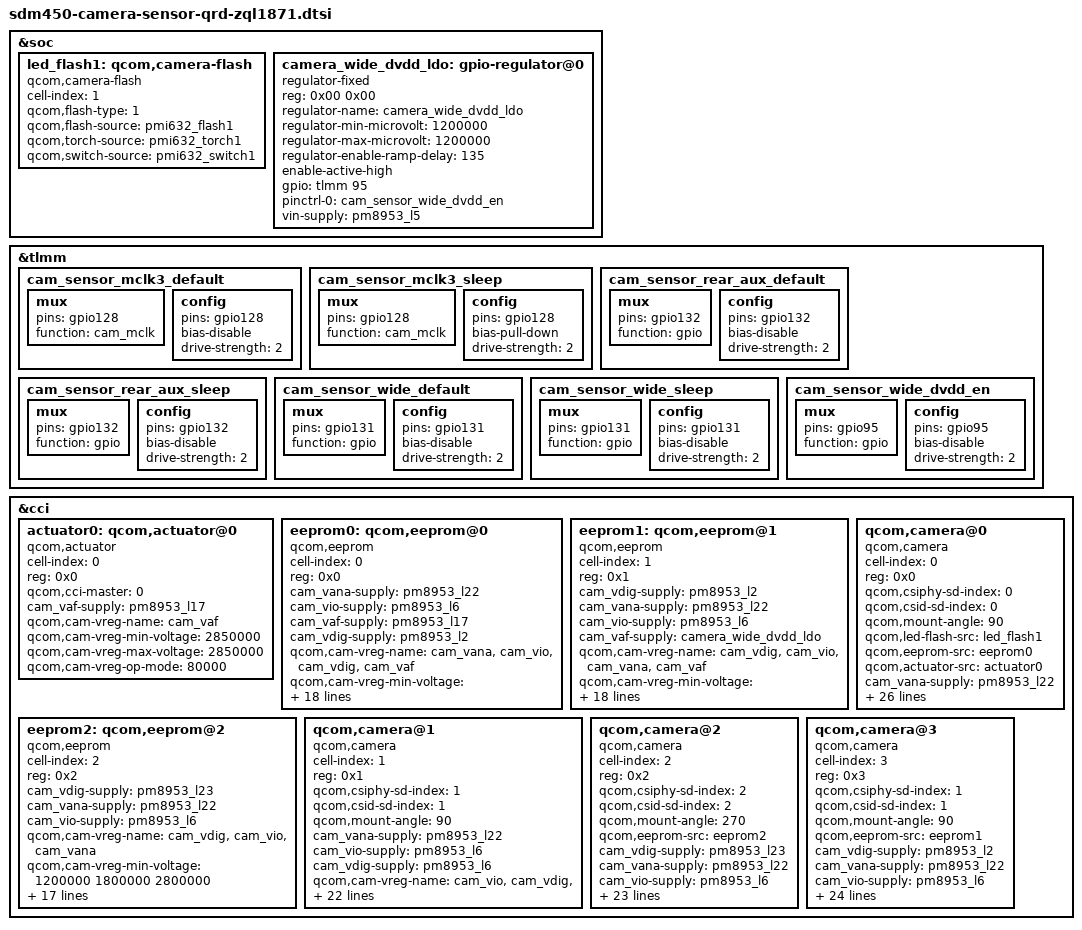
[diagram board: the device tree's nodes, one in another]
/*
 * Copyright (c) 2015-2016, 2018-2019 The Linux Foundation. All rights reserved.
 *
 * This program is free software; you can redistribute it and/or modify
 * it under the terms of the GNU General Public License version 2 and
 * only version 2 as published by the Free Software Foundation.
 *
 * This program is distributed in the hope that it will be useful,
 * but WITHOUT ANY WARRANTY; without even the implied warranty of
 * MERCHANTABILITY or FITNESS FOR A PARTICULAR PURPOSE.  See the
 * GNU General Public License for more details.
 */
/*HS70 code for HS70-58 modify flash switch by chengzhi at 2019/10/22 start*/
&soc {
	led_flash1: qcom,camera-flash {
		cell-index = <1>;
		compatible = "qcom,camera-flash";
		qcom,flash-type = <1>;
		qcom,flash-source = <&pmi632_flash1>;
		qcom,torch-source = <&pmi632_torch1>;
		qcom,switch-source = <&pmi632_switch1>;
	};

	camera_wide_dvdd_ldo: gpio-regulator@0 {
		compatible = "regulator-fixed";
		reg = <0x00 0x00>;
		regulator-name = "camera_wide_dvdd_ldo";
		regulator-min-microvolt = <1200000>;
		regulator-max-microvolt = <1200000>;
		regulator-enable-ramp-delay = <135>;
		enable-active-high;
		gpio = <&tlmm 95 0>;
		pinctrl-names = "default";
		pinctrl-0 = <&cam_sensor_wide_dvdd_en>;
		vin-supply = <&pm8953_l5>;
	};
};
/*HS70 code for HS70-58 modify flash switch by chengzhi at 2019/10/22 end*/

&tlmm{
	cam_sensor_mclk3_default: cam_sensor_mclk3_default {
		/* MCLK3 */
		mux {
			pins = "gpio128";
			function = "cam_mclk";
		};

		config {
			pins = "gpio128";
			bias-disable; /* No PULL */
			drive-strength = <2>; /* 2 MA */
		};
	};

	cam_sensor_mclk3_sleep: cam_sensor_mclk3_sleep {
		/* MCLK3 */
		mux {
			pins = "gpio128";
			function = "cam_mclk";
		};

		config {
			pins = "gpio128";
			bias-pull-down; /* PULL DOWN */
			drive-strength = <2>; /* 2 MA */
		};
	};

	cam_sensor_rear_aux_default: cam_sensor_rear_aux_default {
		/* RESET, STANDBY */
		mux {
			pins = "gpio132";
			function = "gpio";
		};

		config {
			pins = "gpio132";
			bias-disable; /* No PULL */
			drive-strength = <2>; /* 2 MA */
		};
	};

	cam_sensor_rear_aux_sleep: cam_sensor_rear_aux_sleep {
		/* RESET, STANDBY */
		mux {
			pins = "gpio132";
			function = "gpio";
		};

		config {
			pins = "gpio132";
			bias-disable; /* No PULL */
			drive-strength = <2>; /* 2 MA */
		};
	};

	cam_sensor_wide_default: cam_sensor_wide_default {
		/* RESET, STANDBY */
		mux {
			pins = "gpio131";
			function = "gpio";
		};

		config {
			pins = "gpio131";
			bias-disable; /* No PULL */
			drive-strength = <2>; /* 2 MA */
		};
	};

	cam_sensor_wide_sleep: cam_sensor_wide_sleep {
		/* RESET, STANDBY */
		mux {
			pins = "gpio131";
			function = "gpio";
		};

		config {
			pins = "gpio131";
			bias-disable; /* No PULL */
			drive-strength = <2>; /* 2 MA */
		};
	};

	cam_sensor_wide_dvdd_en: cam_sensor_wide_dvdd_en {
		/* RESET, STANDBY */
		mux {
			pins = "gpio95";
			function = "gpio";
		};

		config {
			pins = "gpio95";
			bias-disable; /* No PULL */
			drive-strength = <2>; /* 2 MA */
		};
	};
};

&cci {
	#address-cells = <1>;
	#size-cells = <0>;

	actuator0: qcom,actuator@0 {
		cell-index = <0>;
		reg = <0x0>;
		compatible = "qcom,actuator";
		qcom,cci-master = <0>;
		cam_vaf-supply = <&pm8953_l17>;
		qcom,cam-vreg-name = "cam_vaf";
		qcom,cam-vreg-min-voltage = <2850000>;
		qcom,cam-vreg-max-voltage = <2850000>;
		qcom,cam-vreg-op-mode = <80000>;
	};
	/*HS70 code for HS70-58 add otp node by chengzhi at 2019/10/22 start*/
	eeprom0: qcom,eeprom@0 {
		cell-index = <0>;
		compatible = "qcom,eeprom";
		reg = <0x0>;
		cam_vana-supply = <&pm8953_l22>;
		cam_vio-supply = <&pm8953_l6>;
		cam_vaf-supply = <&pm8953_l17>;
		cam_vdig-supply = <&pm8953_l2>;
		qcom,cam-vreg-name = "cam_vana", "cam_vio",
				"cam_vdig", "cam_vaf";
		qcom,cam-vreg-min-voltage = <2800000 1800000 1050000 2850000>;
		qcom,cam-vreg-max-voltage = <2800000 1800000 1200000 2850000>;
		qcom,cam-vreg-op-mode = <80000 0 105000 100000>;
		pinctrl-names = "cam_default", "cam_suspend";
		pinctrl-0 = <&cam_sensor_mclk0_default
				&cam_sensor_rear_default>;
		pinctrl-1 = <&cam_sensor_mclk0_sleep
				&cam_sensor_rear_sleep>;
		gpios = <&tlmm 26 0>,
			<&tlmm 40 0>;
		qcom,gpio-reset = <1>;
		qcom,gpio-req-tbl-num = <0 1>;
		qcom,gpio-req-tbl-flags = <1 0>;
		qcom,gpio-req-tbl-label = "CAMIF_MCLK0",
			"CAM_RESET0";
		qcom,cci-master = <0>;
		status = "ok";
		clocks = <&clock_gcc clk_mclk0_clk_src>,
				<&clock_gcc clk_gcc_camss_mclk0_clk>;
		clock-names = "cam_src_clk", "cam_clk";
		qcom,clock-rates = <24000000 0>;
	};

	eeprom1: qcom,eeprom@1 {
		cell-index = <1>;
		compatible = "qcom,eeprom";
		reg = <0x1>;
		cam_vdig-supply = <&pm8953_l2>;
		cam_vana-supply = <&pm8953_l22>;
		cam_vio-supply = <&pm8953_l6>;
		cam_vaf-supply = <&camera_wide_dvdd_ldo>;
		qcom,cam-vreg-name = "cam_vdig", "cam_vio", "cam_vana", "cam_vaf";
		qcom,cam-vreg-min-voltage = <1050000 1800000 2800000 1200000>;
		qcom,cam-vreg-max-voltage = <1200000 1800000 2800000 1200000>;
		qcom,cam-vreg-op-mode = <105000 0 80000 105000>;
		pinctrl-names = "cam_default", "cam_suspend";
		pinctrl-0 = <&cam_sensor_mclk2_default
				&cam_sensor_wide_default>;
		pinctrl-1 = <&cam_sensor_mclk2_sleep
				&cam_sensor_wide_sleep>;
		gpios = <&tlmm 28 0>,
			<&tlmm 131 0>;
		qcom,gpio-reset = <1>;
		qcom,gpio-req-tbl-num = <0 1>;
		qcom,gpio-req-tbl-flags = <1 0>;
		qcom,gpio-req-tbl-label = "CAMIF_MCLK2",
					  "CAM_RESET3";
		qcom,cci-master = <1>;
		status = "ok";
		clocks = <&clock_gcc clk_mclk2_clk_src>,
			<&clock_gcc clk_gcc_camss_mclk2_clk>;
		clock-names = "cam_src_clk", "cam_clk";
		qcom,clock-rates = <24000000 0>;
	};

	eeprom2: qcom,eeprom@2 {
		cell-index = <2>;
		compatible = "qcom,eeprom";
		reg = <0x2>;
		cam_vdig-supply = <&pm8953_l23>;
		cam_vana-supply = <&pm8953_l22>;
		cam_vio-supply = <&pm8953_l6>;
		qcom,cam-vreg-name = "cam_vdig", "cam_vio", "cam_vana";
		qcom,cam-vreg-min-voltage = <1200000 1800000 2800000>;
		qcom,cam-vreg-max-voltage = <1200000 1800000 2800000>;
		qcom,cam-vreg-op-mode = <105000 0 80000>;
		pinctrl-names = "cam_default", "cam_suspend";
		pinctrl-0 = <&cam_sensor_mclk1_default
				&cam_sensor_front1_default>;
		pinctrl-1 = <&cam_sensor_mclk1_sleep
				&cam_sensor_front1_sleep>;
		gpios = <&tlmm 27 0>,
			<&tlmm 129 0>;
		qcom,gpio-reset = <1>;
		qcom,gpio-req-tbl-num = <0 1>;
		qcom,gpio-req-tbl-flags = <1 0>;
		qcom,gpio-req-tbl-label = "CAMIF_MCLK1",
					  "CAM_RESET2";
		qcom,cci-master = <1>;
		status = "ok";
		clocks = <&clock_gcc clk_mclk1_clk_src>,
			<&clock_gcc clk_gcc_camss_mclk1_clk>;
		clock-names = "cam_src_clk", "cam_clk";
		qcom,clock-rates = <24000000 0>;
	};
	/*HS70 code for HS70-58 add otp node by chengzhi at 2019/10/22 end*/
	qcom,camera@0 {
		cell-index = <0>;
		compatible = "qcom,camera";
		reg = <0x0>;
		qcom,csiphy-sd-index = <0>;
		qcom,csid-sd-index = <0>;
		qcom,mount-angle = <90>;
		qcom,led-flash-src = <&led_flash1>;
		qcom,eeprom-src = <&eeprom0>;
		qcom,actuator-src = <&actuator0>;
		cam_vana-supply = <&pm8953_l22>;
		cam_vio-supply = <&pm8953_l6>;
		cam_vaf-supply = <&pm8953_l17>;
		cam_vdig-supply = <&pm8953_l2>;
		qcom,cam-vreg-name = "cam_vana", "cam_vio",
				"cam_vdig", "cam_vaf";
		qcom,cam-vreg-min-voltage = <2800000 1800000 1050000 2850000>;
		qcom,cam-vreg-max-voltage = <2800000 1800000 1200000 2850000>;
		qcom,cam-vreg-op-mode = <80000 0 105000 100000>;
		pinctrl-names = "cam_default", "cam_suspend";
		pinctrl-0 = <&cam_sensor_mclk0_default
				&cam_sensor_rear_default>;
		pinctrl-1 = <&cam_sensor_mclk0_sleep
				&cam_sensor_rear_sleep>;
		gpios = <&tlmm 26 0>,
			<&tlmm 40 0>;
		qcom,gpio-reset = <1>;
		qcom,gpio-req-tbl-num = <0 1>;
		qcom,gpio-req-tbl-flags = <1 0>;
		qcom,gpio-req-tbl-label = "CAMIF_MCLK0",
			"CAM_RESET0";
		qcom,sensor-position = <0>;
		qcom,sensor-mode = <0>;
		qcom,cci-master = <0>;
		status = "ok";
		clocks = <&clock_gcc clk_mclk0_clk_src>,
				<&clock_gcc clk_gcc_camss_mclk0_clk>;
		clock-names = "cam_src_clk", "cam_clk";
		qcom,clock-rates = <24000000 0>;
	};

	qcom,camera@1 {
		cell-index = <1>;
		compatible = "qcom,camera";
		reg = <0x1>;
		qcom,csiphy-sd-index = <1>;
		qcom,csid-sd-index = <1>;
		qcom,mount-angle = <90>;
		cam_vana-supply = <&pm8953_l22>;
		cam_vio-supply = <&pm8953_l6>;
		cam_vdig-supply = <&pm8953_l6>;
		qcom,cam-vreg-name = "cam_vio", "cam_vdig", "cam_vana";
		qcom,cam-vreg-min-voltage = <1800000 1800000 2800000>;
		qcom,cam-vreg-max-voltage = <1800000 1800000 2800000>;
		qcom,cam-vreg-op-mode = <0 0 80000>;
		pinctrl-names = "cam_default", "cam_suspend";
		pinctrl-0 = <&cam_sensor_mclk3_default
				&cam_sensor_rear_aux_default>;
		pinctrl-1 = <&cam_sensor_mclk3_sleep
				&cam_sensor_rear_aux_sleep>;
		gpios = <&tlmm 128 0>,
			<&tlmm 132 0>;
		qcom,gpio-reset = <1>;
		qcom,gpio-req-tbl-num = <0 1>;
		qcom,gpio-req-tbl-flags = <1 0>;
		qcom,gpio-req-tbl-label = "CAMIF_MCLK3",
			"CAM_RESET1";
		qcom,sensor-position = <2>;
		qcom,sensor-mode = <1>;
		qcom,cci-master = <1>;
		clocks = <&clock_gcc clk_mclk3_clk_src>,
				<&clock_gcc clk_gcc_camss_mclk3_clk>;
		clock-names = "cam_src_clk", "cam_clk";
		qcom,clock-rates = <24000000 0>;
	};

	qcom,camera@2 {
		cell-index = <2>;
		compatible = "qcom,camera";
		reg = <0x2>;
		qcom,csiphy-sd-index = <2>;
		qcom,csid-sd-index = <2>;
		qcom,mount-angle = <270>;
		qcom,eeprom-src = <&eeprom2>;
		cam_vdig-supply = <&pm8953_l23>;
		cam_vana-supply = <&pm8953_l22>;
		cam_vio-supply = <&pm8953_l6>;
		qcom,cam-vreg-name = "cam_vdig", "cam_vio", "cam_vana";
		qcom,cam-vreg-min-voltage = <1200000 1800000 2800000>;
		qcom,cam-vreg-max-voltage = <1200000 1800000 2800000>;
		qcom,cam-vreg-op-mode = <105000 0 80000>;
		pinctrl-names = "cam_default", "cam_suspend";
		pinctrl-0 = <&cam_sensor_mclk1_default
				&cam_sensor_front1_default>;
		pinctrl-1 = <&cam_sensor_mclk1_sleep
				&cam_sensor_front1_sleep>;
		gpios = <&tlmm 27 0>,
			<&tlmm 129 0>;
		qcom,gpio-reset = <1>;
		qcom,gpio-req-tbl-num = <0 1>;
		qcom,gpio-req-tbl-flags = <1 0>;
		qcom,gpio-req-tbl-label = "CAMIF_MCLK1",
					  "CAM_RESET2";
		qcom,sensor-position = <1>;
		qcom,sensor-mode = <0>;
		qcom,cci-master = <1>;
		status = "ok";
		clocks = <&clock_gcc clk_mclk1_clk_src>,
			<&clock_gcc clk_gcc_camss_mclk1_clk>;
		clock-names = "cam_src_clk", "cam_clk";
		qcom,clock-rates = <24000000 0>;
	};

	qcom,camera@3 {
		cell-index = <3>;
		compatible = "qcom,camera";
		reg = <0x3>;
		qcom,csiphy-sd-index = <1>;
		qcom,csid-sd-index = <1>;
		qcom,mount-angle = <90>;
		qcom,eeprom-src = <&eeprom1>;
		cam_vdig-supply = <&pm8953_l2>;
		cam_vana-supply = <&pm8953_l22>;
		cam_vio-supply = <&pm8953_l6>;
		cam_vaf-supply = <&camera_wide_dvdd_ldo>;
		qcom,cam-vreg-name = "cam_vdig", "cam_vio", "cam_vana", "cam_vaf";
		qcom,cam-vreg-min-voltage = <1050000 1800000 2800000 1200000>;
		qcom,cam-vreg-max-voltage = <1200000 1800000 2800000 1200000>;
		qcom,cam-vreg-op-mode = <105000 0 80000 105000>;
		pinctrl-names = "cam_default", "cam_suspend";
		pinctrl-0 = <&cam_sensor_mclk2_default
				&cam_sensor_wide_default>;
		pinctrl-1 = <&cam_sensor_mclk2_sleep
				&cam_sensor_wide_sleep>;
		gpios = <&tlmm 28 0>,
			<&tlmm 131 0>;
		qcom,gpio-reset = <1>;
		qcom,gpio-req-tbl-num = <0 1>;
		qcom,gpio-req-tbl-flags = <1 0>;
		qcom,gpio-req-tbl-label = "CAMIF_MCLK2",
					  "CAM_RESET3";
		qcom,sensor-position = <1>;
		qcom,sensor-mode = <0>;
		qcom,cci-master = <1>;
		status = "ok";
		clocks = <&clock_gcc clk_mclk2_clk_src>,
			<&clock_gcc clk_gcc_camss_mclk2_clk>;
		clock-names = "cam_src_clk", "cam_clk";
		qcom,clock-rates = <24000000 0>;
	};
};
